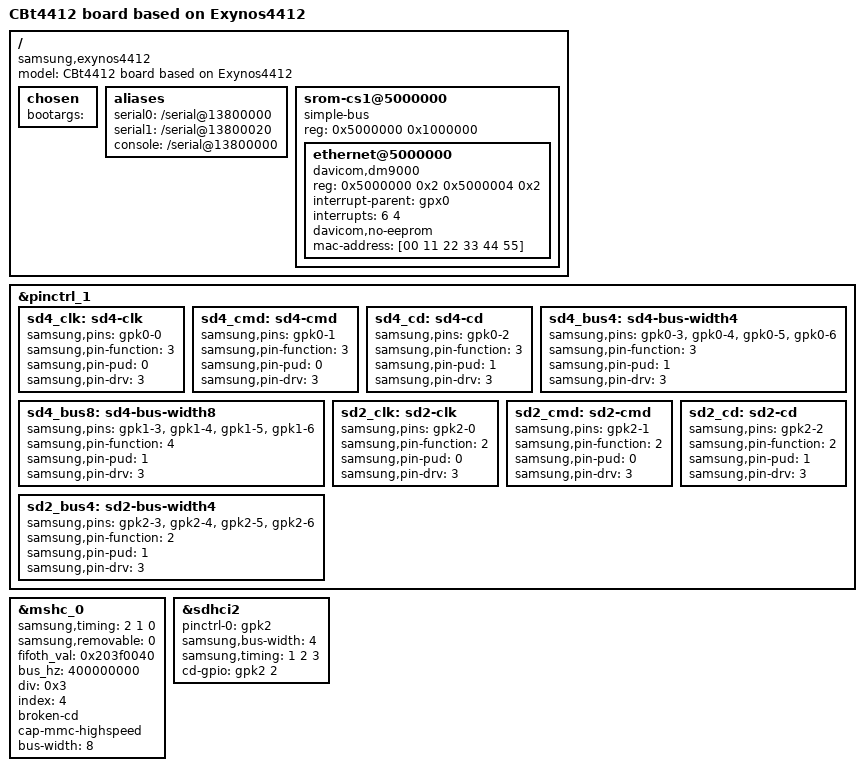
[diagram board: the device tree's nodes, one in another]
// SPDX-License-Identifier: GPL-2.0+
/*
 * Samsung's Exynos4210 based Origen board device tree source
 *
 * Copyright (c) 2014 Samsung Electronics Co., Ltd.
 *		http://www.samsung.com
 */

/dts-v1/;
#include "skeleton.dtsi"
#include "exynos4412.dtsi"
#include "exynos4x12.dtsi"
#include "exynos4.dtsi"

/ {
	model = "CBt4412 board based on Exynos4412";
	compatible = "samsung,exynos4412";

	chosen {
		bootargs ="";
		};

	aliases {
		serial0 = "/serial@13800000";
		serial1 = "/serial@13800020";
		console = "/serial@13800000";
		
	};


	srom-cs1@5000000{
	compatible = "simple-bus";
	#address-cells = <1>;
	#size-cells = <1>;
	reg = <0x5000000 0x1000000>;
	ranges;
	ethernet@5000000{
		compatible = "davicom,dm9000";
		reg = <0x5000000 0x2 0x5000004 0x2>;
		interrupt-parent = <&gpx0>;
		interrupts = <6 4>;
		davicom,no-eeprom;
		mac-address = [00 11 22 33 44 55];
		};	
	};
};

&pinctrl_1{

	sd4_clk: sd4-clk {
		samsung,pins = "gpk0-0";
		samsung,pin-function = <3>;
		samsung,pin-pud = <0>;
		samsung,pin-drv = <3>;
	};

	sd4_cmd: sd4-cmd {
		samsung,pins = "gpk0-1";
		samsung,pin-function = <3>;
		samsung,pin-pud = <0>;
		samsung,pin-drv = <3>;
	};

	sd4_cd: sd4-cd {
		samsung,pins = "gpk0-2";
		samsung,pin-function = <3>;
		samsung,pin-pud = <1>;
		samsung,pin-drv = <3>;
	};


	sd4_bus4: sd4-bus-width4 {
		samsung,pins = "gpk0-3", "gpk0-4", "gpk0-5", "gpk0-6";
		samsung,pin-function = <3>;
		samsung,pin-pud = <1>;
		samsung,pin-drv = <3>;
	};

	sd4_bus8: sd4-bus-width8 {
		samsung,pins = "gpk1-3", "gpk1-4", "gpk1-5", "gpk1-6";
		samsung,pin-function = <4>;
		samsung,pin-pud = <1>;
		samsung,pin-drv = <3>;
	};

	sd2_clk: sd2-clk {
		samsung,pins = "gpk2-0";
		samsung,pin-function = <2>;
		samsung,pin-pud = <0>;
		samsung,pin-drv = <3>;
	};

	sd2_cmd: sd2-cmd {
		samsung,pins = "gpk2-1";
		samsung,pin-function = <2>;
		samsung,pin-pud = <0>;
		samsung,pin-drv = <3>;
	};

	sd2_cd: sd2-cd {
		samsung,pins = "gpk2-2";
		samsung,pin-function = <2>;
		samsung,pin-pud = <1>;
		samsung,pin-drv = <3>;
	};

	sd2_bus4: sd2-bus-width4 {
		samsung,pins = "gpk2-3", "gpk2-4", "gpk2-5", "gpk2-6";
		samsung,pin-function = <2>;
		samsung,pin-pud = <1>;
		samsung,pin-drv = <3>;
	};

};

&mshc_0 {
	samsung,timing = <2 1 0>;
	samsung,removable = <0>;
	fifoth_val = <0x203f0040>;
	bus_hz = <400000000>;
	div = <0x3>;
	index = <4>;

	broken-cd;
	cap-mmc-highspeed;
	bus-width = <8>;
	status = "okay";
};

&sdhci2 {
	pinctrl-0 = <&gpk2>;
	samsung,bus-width = <4>;
	samsung,timing = <1 2 3>;
	cd-gpio = <&gpk2 2 0>;
	status = "okay";
};
